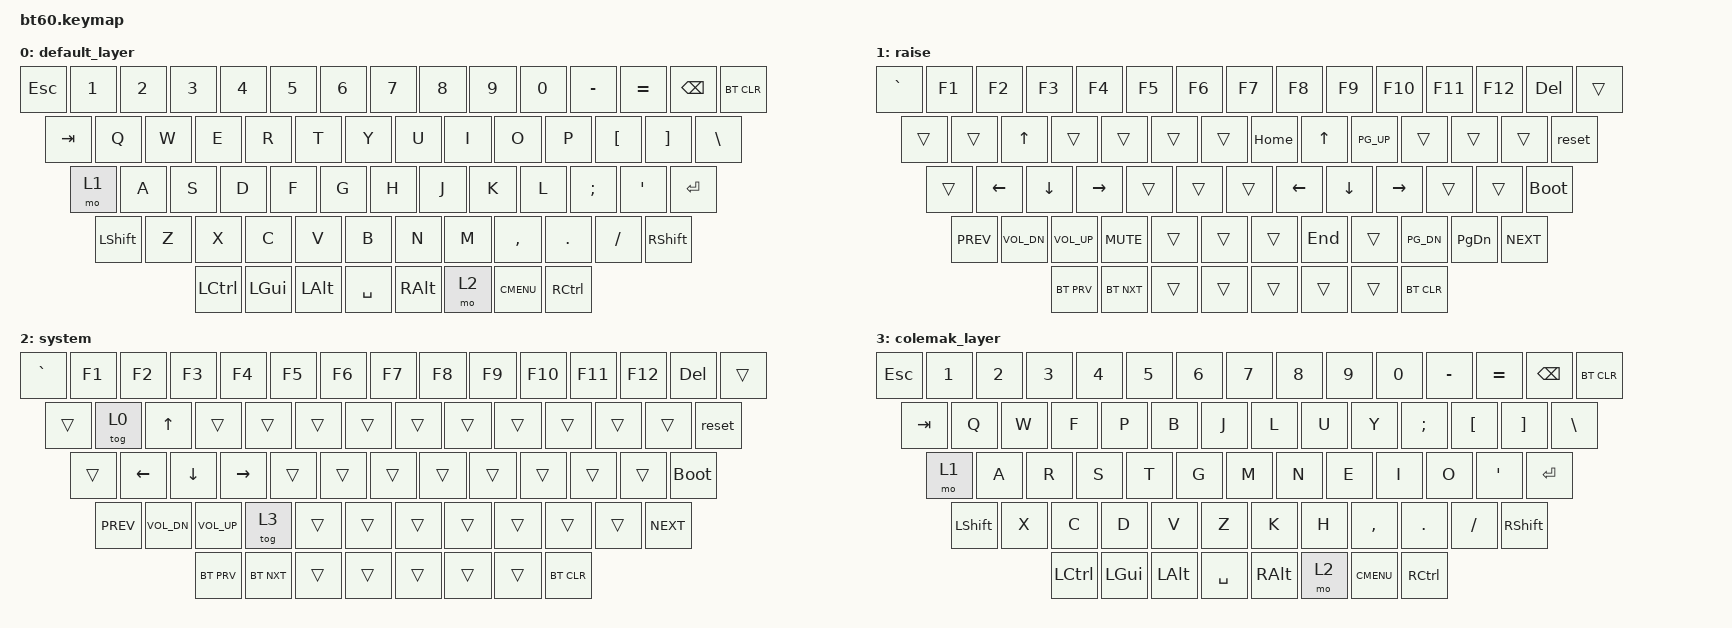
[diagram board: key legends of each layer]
#include <behaviors.dtsi>
#include <dt-bindings/zmk/keys.h>
#include <dt-bindings/zmk/bt.h>

/ {
	keymap {
		compatible = "zmk,keymap";

		default_layer {
				// ------------------------------------------------------------------------------------------
				// | ESC |  1  |  2  |  3  |  4  |  5  |  6  |  7  |  8  |  9  |  0  |  -  |  =  |   BKSP   | DEL
				// | TAB  |  Q  |  W  |  E  |  R  |  T  |  Y  |  U  |  I  |  O  |  P  |  [  |  ]  |   |    |
				// | CAPS  |  A  |  S  |  D  |  F  |  G  |  H  |  J  |  K  |  L  |  ;  |  '  |     ENTER    |
				// |  SHIFT    |  Z  |  X  |  C  |  V  |  B  |  N  |  M  |  ,  |  .  | /   |      SHIFT     |
				// |  CTL  |  WIN  |  ALT  |            SPACE               | ALT | 1    |  MENU    |  CTRL    |
				// ------------------------------------------------------------------------------------------
			bindings = <
				&kp ESC &kp N1 &kp N2 &kp N3 &kp N4 &kp N5 &kp N6 &kp N7 &kp  N8   &kp  N9 &kp  N0  &kp MINUS &kp EQUAL &kp BSPC &bt BT_CLR
				&kp TAB  &kp Q  &kp W  &kp E  &kp R  &kp T  &kp Y  &kp U  &kp  I    &kp  O  &kp  P   &kp LBKT &kp RBKT  &kp BSLH
				&mo 1  &kp A  &kp S  &kp D  &kp F  &kp G  &kp H  &kp J  &kp  K    &kp  L  &kp SEMI &kp SQT           &kp RET
				&kp LSHFT  &kp Z  &kp X  &kp C  &kp V  &kp B  &kp N  &kp M  &kp COMMA &kp DOT &kp FSLH             &kp RSHFT
				&kp LCTRL &kp LGUI &kp LALT            &kp SPACE                          &kp RALT  &mo 2 &kp K_CMENU &kp RCTRL
			>;
			sensor-bindings = <&inc_dec_kp C_VOL_UP C_VOL_DN>;
		};
		
		raise {
			bindings = <
				&kp GRAVE &kp F1 &kp F2 &kp F3 &kp F4 &kp F5 &kp F6 &kp F7 &kp  F8   &kp  F9 &kp  F10  &kp F11 &kp F12   &kp DEL &trans
				&trans &trans &kp UP &trans &trans &trans &trans &kp HOME &kp UP PG_UP  &trans &trans &trans &reset
				&trans    &kp LEFT &kp DOWN &kp RIGHT &trans &trans &trans &kp LEFT &kp DOWN &kp RIGHT &trans  &trans   &bootloader
				&kp C_PREV &kp C_VOL_DN &kp C_VOL_UP &kp C_MUTE &trans &trans &trans &kp END &trans PG_DN  &kp PG_DN  &kp C_NEXT
				&bt BT_PRV &bt BT_NXT  &trans              &trans                            &trans   &trans   &trans &bt BT_CLR
			>;
			sensor-bindings = <&inc_dec_kp C_VOL_UP C_VOL_DN>;
		};
		
		system {
			bindings = <
				&kp GRAVE &kp F1 &kp F2 &kp F3 &kp F4 &kp F5 &kp F6 &kp F7 &kp  F8   &kp  F9 &kp  F10  &kp F11 &kp F12   &kp DEL &trans
				&trans &tog 0 &kp UP &trans &trans &trans &trans &trans &trans &trans &trans &trans &trans &reset
				&trans    &kp LEFT &kp DOWN &kp RIGHT &trans &trans &trans &trans &trans &trans &trans  &trans   &bootloader
				&kp C_PREV &kp C_VOL_DN &kp C_VOL_UP &tog 3 &trans &trans &trans &trans &trans &trans &trans  &kp C_NEXT
				&bt BT_PRV &bt BT_NXT  &trans              &trans                            &trans   &trans   &trans &bt BT_CLR
			>;
			sensor-bindings = <&inc_dec_kp C_VOL_UP C_VOL_DN>;
		};
		
		colemak_layer {
				// ------------------------------------------------------------------------------------------
				// | ESC |  1  |  2  |  3  |  4  |  5  |  6  |  7  |  8  |  9  |  0  |  -  |  =  |   BKSP   | DEL
				// | TAB  |  Q  |  W  |  E  |  R  |  T  |  Y  |  U  |  I  |  O  |  P  |  [  |  ]  |   |    |
				// | CAPS  |  A  |  S  |  D  |  F  |  G  |  H  |  J  |  K  |  L  |  ;  |  '  |     ENTER    |
				// |  SHIFT    |  Z  |  X  |  C  |  V  |  B  |  N  |  M  |  ,  |  .  | /   |      SHIFT     |
				// |  CTL  |  WIN  |  ALT  |            SPACE               | ALT | 1    |  MENU    |  CTRL    |
				// ------------------------------------------------------------------------------------------
			bindings = <
				&kp ESC &kp N1 &kp N2 &kp N3 &kp N4 &kp N5 &kp N6 &kp N7 &kp  N8   &kp  N9 &kp  N0  &kp MINUS &kp EQUAL &kp BSPC &bt BT_CLR
				&kp TAB  &kp Q  &kp W  &kp F  &kp P  &kp B  &kp J  &kp L  &kp  U    &kp  Y  &kp  SEMI &kp LBKT &kp RBKT  &kp BSLH
				&mo 1  &kp A  &kp R  &kp S  &kp T  &kp G  &kp M  &kp N  &kp  E    &kp  I  &kp O &kp SQT           &kp RET
				&kp LSHFT  &kp X  &kp C  &kp D  &kp V  &kp Z  &kp K  &kp H  &kp COMMA &kp DOT &kp FSLH             &kp RSHFT
				&kp LCTRL &kp LGUI &kp LALT            &kp SPACE                          &kp RALT  &mo 2 &kp K_CMENU &kp RCTRL
			>;
			sensor-bindings = <&inc_dec_kp C_VOL_UP C_VOL_DN>;
		};
	};
};
